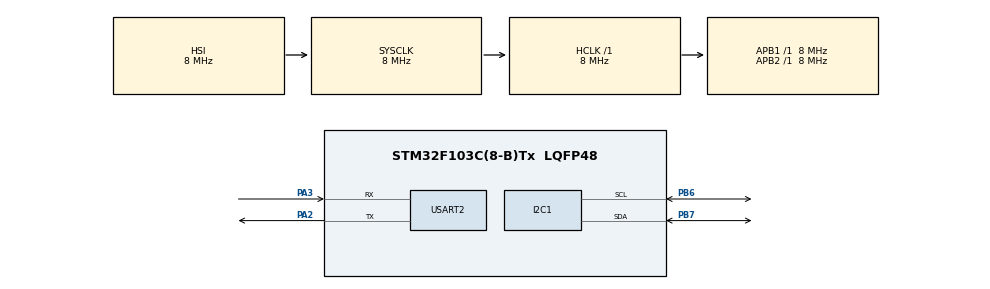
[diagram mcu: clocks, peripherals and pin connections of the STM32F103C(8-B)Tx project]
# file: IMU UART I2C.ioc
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Mcu.Family=STM32F1
Mcu.Name=STM32F103C(8-B)Tx
Mcu.Package=LQFP48
NVIC.PriorityGroup=NVIC_PRIORITYGROUP_4
PA13.Mode=Serial_Wire
PA13.Signal=SYS_JTMS-SWDIO
PA14.Mode=Serial_Wire
PA14.Signal=SYS_JTCK-SWCLK
PA2.Mode=Asynchronous
PA2.Signal=USART2_TX
PA3.Mode=Asynchronous
PA3.Signal=USART2_RX
PB6.Mode=I2C
PB6.Signal=I2C1_SCL
PB7.Mode=I2C
PB7.Signal=I2C1_SDA
ProjectManager.HeapSize=0x200
ProjectManager.StackSize=0x400
ProjectManager.TargetToolchain=STM32CubeIDE
RCC.AHBFreq_Value=8000000
RCC.APB1Freq_Value=8000000
RCC.APB1TimCLKDivider=1
RCC.APB1TimFreq_Value=8000000
RCC.APB2Freq_Value=8000000
RCC.APB2TimFreq_Value=8000000
RCC.HCLKFreq_Value=8000000
RCC.SYSCLKFreq_VALUE=8000000
RCC.USBFreq_Value=8000000
USART2.VirtualMode=VM_ASYNC
board=custom

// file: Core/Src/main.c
/* USER CODE BEGIN Header */
/**
  ******************************************************************************
  * @file           : main.c
  * @brief          : Main program body
  ******************************************************************************
  * @attention
  *
  * Copyright (c) 2023 STMicroelectronics.
  * All rights reserved.
  *
  * This software is licensed under terms that can be found in the LICENSE file
  * in the root directory of this software component.
  * If no LICENSE file comes with this software, it is provided AS-IS.
  *
  ******************************************************************************
  */
/* USER CODE END Header */
#include "main.h"

I2C_HandleTypeDef hi2c1;

UART_HandleTypeDef huart2;

/* USER CODE BEGIN PV */

uint8_t tx_buffer1[] = "DATA 1";
uint8_t tx_buffer2[] = "DATA 2";

uint16_t tx_size = sizeof(tx_buffer1);
uint16_t tx_size2 = sizeof(tx_buffer2);

uint8_t uart_rx_data;

/* USER CODE END PV */

void SystemClock_Config(void);
static void MX_GPIO_Init(void);
static void MX_I2C1_Init(void);
static void MX_USART2_UART_Init(void);

int main(void)
{

  /* MCU Configuration--------------------------------------------------------*/

  /* Reset of all peripherals, Initializes the Flash interface and the Systick. */
  HAL_Init();

  /* Configure the system clock */
  SystemClock_Config();

  /* Initialize all configured peripherals */
  MX_GPIO_Init();
  MX_I2C1_Init();
  MX_USART2_UART_Init();

  /* Infinite loop */
  while (1)
  {

	  HAL_UART_Receive(&huart2, &uart_rx_data, 1, HAL_MAX_DELAY);

	  	switch(uart_rx_data)
	  		{
	  			case 0XAA : {
	  							HAL_UART_Transmit_IT(&huart2, tx_buffer1, tx_size );
	  								HAL_Delay(500);
	  						}
	  			break;

	  			case 0XAB : {	  HAL_UART_Transmit_IT(&huart2, tx_buffer2, tx_size2 );
	  								HAL_Delay(500);
	  						}
	  			break;

	  			case 0XAC : {	HAL_UART_Transmit_IT(&huart2, "DATA 3", 6);
	  								HAL_Delay(500);
	  						}
	  			break;

	  			case 0XAD : {HAL_UART_Transmit_IT(&huart2, "DATA 4", 6 );
	  				  				HAL_Delay(500);
	  						}
	  			break;

	  			case 0XBA : {	  HAL_UART_Transmit_IT(&huart2, "DATA 5", 6 );
	  				  				HAL_Delay(500);
	  				  		}
	  			break;

	  			case 0XBB : {	HAL_UART_Transmit_IT(&huart2, "DATA 6", 6);
	  				  				HAL_Delay(500);
	  				  		}
	  			break;

	  			case 0XBC : {
	  							HAL_UART_Transmit_IT(&huart2, "DATA 7", 6);
	  								HAL_Delay(500);
	  						}
	  			break;

	  			case 0XBD : {	  HAL_UART_Transmit_IT(&huart2, "DATA 8", 6);
	  								HAL_Delay(500);
	  						}
	  			break;

	  			case 0XCA : {	HAL_UART_Transmit_IT(&huart2, "DATA 9", 6);
	  								HAL_Delay(500);
	  						}
	  			break;

	  			case 0XDA : {HAL_UART_Transmit_IT(&huart2, "DATA 10", 7 );
	  				  				HAL_Delay(500);
	  						}
	  			break;

	  			case 0XDB : {	  HAL_UART_Transmit_IT(&huart2, "DATA 11", 7 );
	  				  				HAL_Delay(500);
	  				  		}
	  			break;

	  			case 0XDC : {	HAL_UART_Transmit_IT(&huart2, "DATA 12", 7);
	  				  				HAL_Delay(500);
	  				  		}
	  			break;

	  			case 0XEA : {
	  							HAL_UART_Transmit_IT(&huart2, "DATA 13", 7);
	  								HAL_Delay(500);
	  						}
	  			break;

	  			case 0XEB : {	  HAL_UART_Transmit_IT(&huart2, "DATA 14", 7);
	  								HAL_Delay(500);
	  						}
	  			break;

	  		}

	    }

	  }

void SystemClock_Config(void)
{
  RCC_OscInitTypeDef RCC_OscInitStruct = {0};
  RCC_ClkInitTypeDef RCC_ClkInitStruct = {0};

  /** Initializes the RCC Oscillators according to the specified parameters
  * in the RCC_OscInitTypeDef structure.
  */
  RCC_OscInitStruct.OscillatorType = RCC_OSCILLATORTYPE_HSI;
  RCC_OscInitStruct.HSIState = RCC_HSI_ON;
  RCC_OscInitStruct.HSICalibrationValue = RCC_HSICALIBRATION_DEFAULT;
  RCC_OscInitStruct.PLL.PLLState = RCC_PLL_NONE;
  if (HAL_RCC_OscConfig(&RCC_OscInitStruct) != HAL_OK)
  {
    Error_Handler();
  }

  /** Initializes the CPU, AHB and APB buses clocks
  */
  RCC_ClkInitStruct.ClockType = RCC_CLOCKTYPE_HCLK|RCC_CLOCKTYPE_SYSCLK
                              |RCC_CLOCKTYPE_PCLK1|RCC_CLOCKTYPE_PCLK2;
  RCC_ClkInitStruct.SYSCLKSource = RCC_SYSCLKSOURCE_HSI;
  RCC_ClkInitStruct.AHBCLKDivider = RCC_SYSCLK_DIV1;
  RCC_ClkInitStruct.APB1CLKDivider = RCC_HCLK_DIV1;
  RCC_ClkInitStruct.APB2CLKDivider = RCC_HCLK_DIV1;

  if (HAL_RCC_ClockConfig(&RCC_ClkInitStruct, FLASH_LATENCY_0) != HAL_OK)
  {
    Error_Handler();
  }
}

static void MX_I2C1_Init(void)
{

  hi2c1.Instance = I2C1;
  hi2c1.Init.ClockSpeed = 100000;
  hi2c1.Init.DutyCycle = I2C_DUTYCYCLE_2;
  hi2c1.Init.OwnAddress1 = 0;
  hi2c1.Init.AddressingMode = I2C_ADDRESSINGMODE_7BIT;
  hi2c1.Init.DualAddressMode = I2C_DUALADDRESS_DISABLE;
  hi2c1.Init.OwnAddress2 = 0;
  hi2c1.Init.GeneralCallMode = I2C_GENERALCALL_DISABLE;
  hi2c1.Init.NoStretchMode = I2C_NOSTRETCH_DISABLE;
  if (HAL_I2C_Init(&hi2c1) != HAL_OK)
  {
    Error_Handler();
  }

}

static void MX_USART2_UART_Init(void)
{

  huart2.Instance = USART2;
  huart2.Init.BaudRate = 115200;
  huart2.Init.WordLength = UART_WORDLENGTH_8B;
  huart2.Init.StopBits = UART_STOPBITS_1;
  huart2.Init.Parity = UART_PARITY_NONE;
  huart2.Init.Mode = UART_MODE_TX_RX;
  huart2.Init.HwFlowCtl = UART_HWCONTROL_NONE;
  huart2.Init.OverSampling = UART_OVERSAMPLING_16;
  if (HAL_UART_Init(&huart2) != HAL_OK)
  {
    Error_Handler();
  }

}

static void MX_GPIO_Init(void)
{

  /* GPIO Ports Clock Enable */
  __HAL_RCC_GPIOA_CLK_ENABLE();
  __HAL_RCC_GPIOB_CLK_ENABLE();

}

void Error_Handler(void)
{
  __disable_irq();
  while (1)
  {
  }
}
